# haltium_application register map
Vendor: Nordic Semiconductor; Series: nRFHaltium; File version: 1
CPU: CM33 r0p4, little endian, MPU, FPU, 3 interrupt priority bits, 480 interrupts
Registers are 32-bit, read-write, reset 0x0 unless marked. A register's access mark holds for its fields unless they carry their own. Offsets are from the block's base; [hi:lo] are bit positions; lines under a group give offsets from that group; 'fields as' and 'values as' point back to an identical list.

## HSFLL_S — HSFLL
Base 0x5200D000
0x00 TASKS_START wo — Start the HSFLL
  [0] TASKS_START
    1=Trigger task
0x04 TASKS_STOP wo — Stop the HSFLL
  [0] TASKS_STOP
    1=Trigger task
0x08 TASKS_SLEEP wo — Request the HSFLL into sleep mode
  [0] TASKS_SLEEP
    1=Trigger task
0x0C TASKS_WAKEUP wo — Wakeup the HSFLL from sleep mode
  [0] TASKS_WAKEUP
    1=Trigger task
0x10 TASKS_FREQMEAS wo — Start frequency measurement in software-controlled mode
  [0] TASKS_FREQMEAS
    1=Trigger task
0x14 TASKS_FREQCHANGE wo — Trigger frequency change
  [0] TASKS_FREQCHANGE
    1=Trigger task
0x100 EVENTS_STARTED — HSFLL started
  [0] EVENTS_STARTED
    0=NotGenerated (Event not generated); 1=Generated (Event generated)
0x104 EVENTS_STOPPED — HSFLL stopped
  [0] EVENTS_STOPPED
    values as EVENTS_STARTED.EVENTS_STARTED
0x108 EVENTS_WOKEUP — HSFLL woke up
  [0] EVENTS_WOKEUP
    values as EVENTS_STARTED.EVENTS_STARTED
0x10C EVENTS_FREQMDONE — Frequency measurement done
  [0] EVENTS_FREQMDONE
    values as EVENTS_STARTED.EVENTS_STARTED
0x110 EVENTS_FREQCHANGED — Frequency change done
  [0] EVENTS_FREQCHANGED
    values as EVENTS_STARTED.EVENTS_STARTED
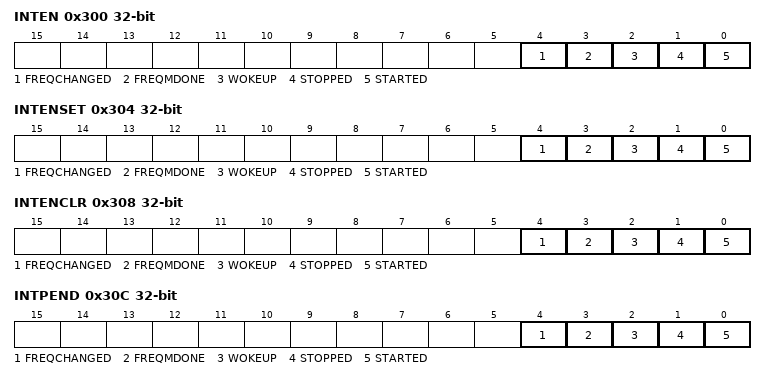
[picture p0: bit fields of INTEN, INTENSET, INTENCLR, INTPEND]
0x300 INTEN — Enable or disable interrupt
  [all] fields
    0=Disabled; 1=Enabled
  [4] FREQCHANGED — Enable or disable interrupt for event FREQCHANGED
  [3] FREQMDONE — Enable or disable interrupt for event FREQMDONE
  [2] WOKEUP — Enable or disable interrupt for event WOKEUP
  [1] STOPPED — Enable or disable interrupt for event STOPPED
  [0] STARTED — Enable or disable interrupt for event STARTED
0x304 INTENSET — Enable interrupt
  [all] fields
    on read: 0=Disabled (Read: Disabled); 1=Enabled (Read: Enabled) | on write: 1=Set (Enable)
  [4] FREQCHANGED — Write '1' to enable interrupt for event FREQCHANGED
  [3] FREQMDONE — Write '1' to enable interrupt for event FREQMDONE
  [2] WOKEUP — Write '1' to enable interrupt for event WOKEUP
  [1] STOPPED — Write '1' to enable interrupt for event STOPPED
  [0] STARTED — Write '1' to enable interrupt for event STARTED
0x308 INTENCLR — Disable interrupt
  [all] fields
    on read: 0=Disabled (Read: Disabled); 1=Enabled (Read: Enabled) | on write: 1=Clear (Disable)
  [4] FREQCHANGED — Write '1' to disable interrupt for event FREQCHANGED
  [3] FREQMDONE — Write '1' to disable interrupt for event FREQMDONE
  [2] WOKEUP — Write '1' to disable interrupt for event WOKEUP
  [1] STOPPED — Write '1' to disable interrupt for event STOPPED
  [0] STARTED — Write '1' to disable interrupt for event STARTED
0x30C INTPEND ro — Pending interrupts
  [all] fields
    on read: 0=NotPending (Read: Not pending); 1=Pending (Read: Pending)
  [4] FREQCHANGED — Read pending status of interrupt for event FREQCHANGED
  [3] FREQMDONE — Read pending status of interrupt for event FREQMDONE
  [2] WOKEUP — Read pending status of interrupt for event WOKEUP
  [1] STOPPED — Read pending status of interrupt for event STOPPED
  [0] STARTED — Read pending status of interrupt for event STARTED
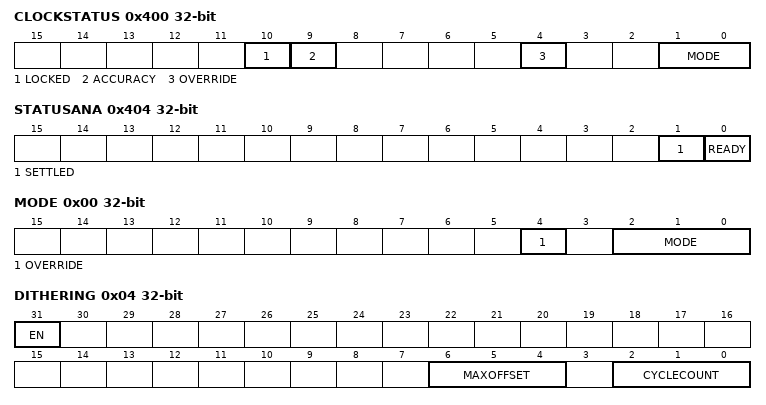
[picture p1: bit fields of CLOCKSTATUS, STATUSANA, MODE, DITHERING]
0x400 CLOCKSTATUS ro
  [10] LOCKED — The HSFLL lock status.
    0=Not locked to reference clock; 1=Locked to reference clock
  [9] ACCURACY — Clock accuracy.
    0=OutsideLimit (Clock accuracy is outside 2 percent.); 1=WithinLimit (Clock accuracy is within 2 percent.)
  [4] OVERRIDE — HSFLL Override mode.
    0=Disabled (Override mode disabled.); 1=Enabled (Override mode enabled.)
  [1:0] MODE — The HSFLL operating mode.
    0=Open loop mode; 1=Closed loop mode; 2=Bypass mode
0x404 STATUSANA ro — Status of analog module output signals
  [1] SETTLED — Current value of the SETTLED signal from the analog module
  [0] READY — Current value of the READY signal from the analog module
0x410 CONFIG group — Unspecified
  0x00 CFG — HSFLL configuration
    [3:0] CFG — Signal CFG[3:0] of analog module
0x420 FREQM group — Unspecified
  0x00 DONE ro — Frequency measurement done status
    [0] DONE — Measurement done.
      0=InProgress (Frequency measurement is in progress.); 1=Completed (Frequency measurement is completed.)
  0x04 ERROR ro — Frequency measurement error status
    [0] ERROR — Error status.
      1=OutsideLimit (Frequency exceeded the accuracy 2 percent in closed loop mode.); 0=WithinLimit (Frequency stayed within accuracy 2 percent in closed loop mode.)
  0x08 MEAS ro — Frequency measurement
    [10:0] VALUE — Last frequency measurement value.
0x440 TRIM group — Unspecified
  0x00 VSUP — Internal regulator voltage supply level trimming
    [4:0] VALUE — Trim value.
  0x04 COARSE — Coarse frequency trimming
    [9:0] VALUE — Trim value.
  0x08 FINE — Fine frequency trimming
    [10:0] VALUE — Trim value.
0x460 CLOCKCTRL group — Unspecified
  0x00 MODE — Clock control
    [4] OVERRIDE — HSFLL override mode.
      values as CLOCKSTATUS.OVERRIDE
    [2:0] MODE — The HSFLL operating mode.
      0=Auto (The PCGC controls the mode automatically.); 1=Open loop mode; 2=Closed loop mode; 3=Bypass mode
  0x04 DITHERING — Clock dithering configuration
    [31] EN — Enable the clock dithering
      0=Disabled (Clock dithering is disabled); 1=Enabled (Clock dithering is enabled)
    [6:4] MAXOFFSET — Maximum offset configuration for clock dithering
    [2:0] CYCLECOUNT — Cycle count configuration for clock dithering
  0x08 MULT reset 0xA — Multiplication factor
    [3:0] VAL — Multiplication factor value.
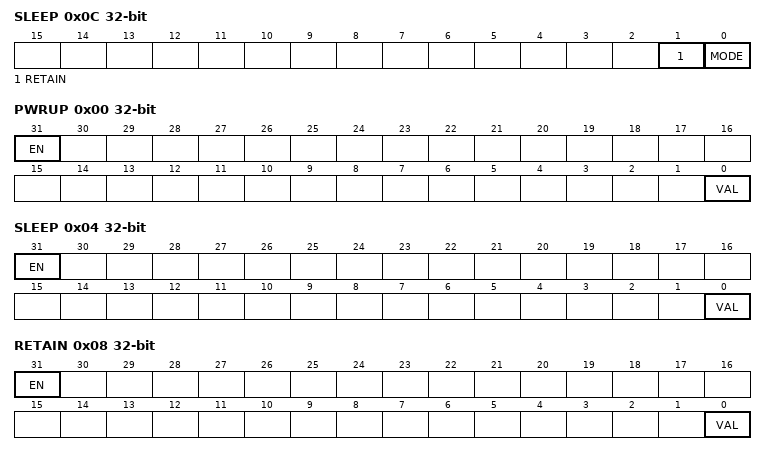
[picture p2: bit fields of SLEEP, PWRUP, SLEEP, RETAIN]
  0x0C SLEEP — Sleep configuration
    [1] RETAIN
      0=Disabled (No retention while powered down); 1=Enabled (Retain all inputs while powered down)
    [0] MODE — HSFLL sleep mode.
      0=Normal mode operation; 1=Sleep (Power down the HSFLL core)
  0x10 RETAINFINETRIM — Fine trim retain control
    [0] RETAIN — Retain control
      0=NoRetain; 1=Retain control when HSFLL goes to open-loop mode
  0x14 OVERRIDELOCKED — Override the LOCKED signal
    [0] OVERRIDE
      0=NoOperation; 1=Override
0x480 MIRROR reset 0x1 — Enable LOCK for mirrored registers
  [0] LOCK — Lock for mirrored registers
    0=Disabled (Lock disabled); 1=Enabled (Lock enabled)
0x500 OVERRIDE group — Unspecified
  0x00 PWRUP — Override the PWRUP signal to the analog module
    [31] EN — Enable the override
      0=Disabled (Override is disabled); 1=Enabled (Override is enabled)
    [0] VAL — Override value for the signal
  0x04 SLEEP — Override the SLEEP signal to the analog module
    fields as OVERRIDE.PWRUP
  0x08 RETAIN — Override the RETAIN signal to the analog module
    fields as OVERRIDE.PWRUP
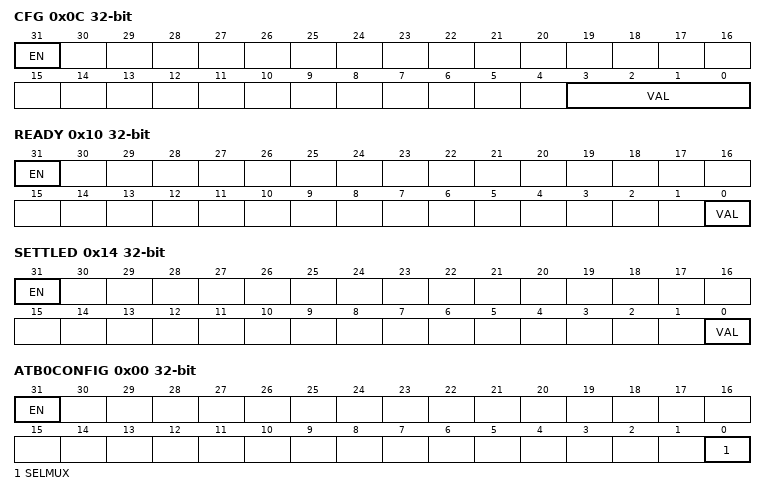
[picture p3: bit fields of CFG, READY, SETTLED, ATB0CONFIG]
  0x0C CFG — Override the CFG signal to the analog module
    [31] EN — Enable the override
      values as OVERRIDE.PWRUP.EN
    [3:0] VAL — Override value for the signal
  0x10 READY — Override the READY signal from the analog module
    [31] EN — Enable the override
      values as OVERRIDE.PWRUP.EN
    [0] VAL — Current value of the signal
  0x14 SETTLED — Override the SETTLED signal from the analog module
    fields as OVERRIDE.READY
0x600 DFT group — Unspecified
  0x00 ATB0CONFIG — Analog Test Bus 0 (ATB0) configuration
    [31] EN — Enable the analog test bus
      0=Disabled (Analog test bus is disabled); 1=Enabled (Analog test bus is enabled)
    [0] SELMUX — Select multiplexer for ATB0
      0=HiZ; 1=VREGOUT
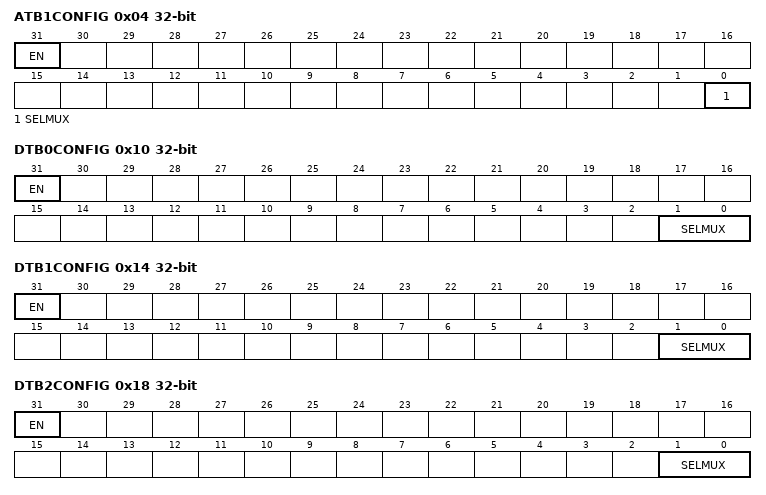
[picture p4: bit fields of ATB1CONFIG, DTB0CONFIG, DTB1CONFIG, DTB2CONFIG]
  0x04 ATB1CONFIG — Analog Test Bus 1 (ATB1) configuration
    [31] EN — Enable the analog test bus
      values as DFT.ATB0CONFIG.EN
    [0] SELMUX — Select multiplexer for ATB1
      0=HiZ
  0x10 DTB0CONFIG — Digital Test Bus 0 (DTB0) configuration
    [31] EN — Enable the digital test bus
      0=Disabled (Digital test bus is disabled); 1=Enabled (Digital test bus is enabled)
    [1:0] SELMUX — Select multiplexer for DTB0
      0=VSS; 1=OSCDIV256INT (OSC_DIV256_INT_0V8 selected); 2=SETTLEDDCO400M (SETTLED_DCO400M_AO_0V8 selected); 3=PWRUPDCO400M (PWRUP_DCO400M_AO_0V8 selected)
  0x14 DTB1CONFIG — Digital Test Bus 1 (DTB1) configuration
    [31] EN — Enable the digital test bus
      values as DFT.DTB0CONFIG.EN
    [1:0] SELMUX — Select multiplexer for DTB1
      0=VSS; 1=RETAINDCO400M (RETAIN_DCO400M_AO_0V8 selected); 2=SETTLEDDCO400M (SETTLED_DCO400M_AO_0V8 selected); 3=OSCDCO400M (OSC_DCO400M_0V8 selected)
  0x18 DTB2CONFIG — Digital Test Bus 2 (DTB2) configuration
    [31] EN — Enable the digital test bus
      values as DFT.DTB0CONFIG.EN
    [1:0] SELMUX — Select multiplexer for DTB2
      0=VSS; 1=SETTLEDDCO400M (SETTLED_DCO400M_AO_0V8 selected); 2=READYDCO400M (READY_DCO400M_AO_0V8 selected); 3=OSCDIV128INT (OSC_DIV128_INT_0V8 selected)
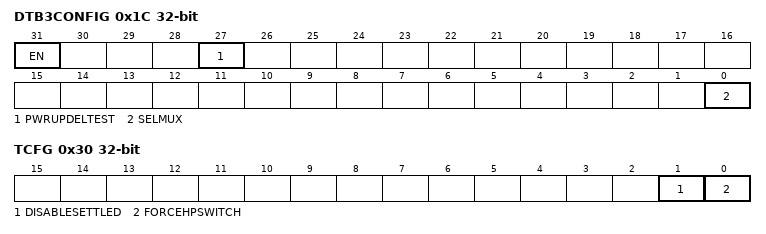
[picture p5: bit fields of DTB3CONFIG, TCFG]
  0x1C DTB3CONFIG — Digital Test Bus 3 (DTB3) configuration
    [31] EN — Enable the digital test bus
      values as DFT.DTB0CONFIG.EN
    [27] PWRUPDELTEST — Enable the PWRUP delay test circuit
      0=Disabled (PWRUP delay test circuit is disabled); 1=Enabled (PWRUP delay test circuit is enabled)
    [0] SELMUX — Select multiplexer for DTB3
      0=VSS; 1=SETTLEDDCO400M (SETTLED_DCO400M_AO_0V8 selected)
  0x30 TCFG — Test mode configuration
    [1] DISABLESETTLED — Disable settled signal to mute output clock
      0=Disabled (Disable settled signal is disabled); 1=Enabled (Disable settled signal is enabled)
    [0] FORCEHPSWITCH — Force HP switch in regulator ON
      0=Disabled (Force HP switch is disabled); 1=Enabled (Force HP switch is enabled)
